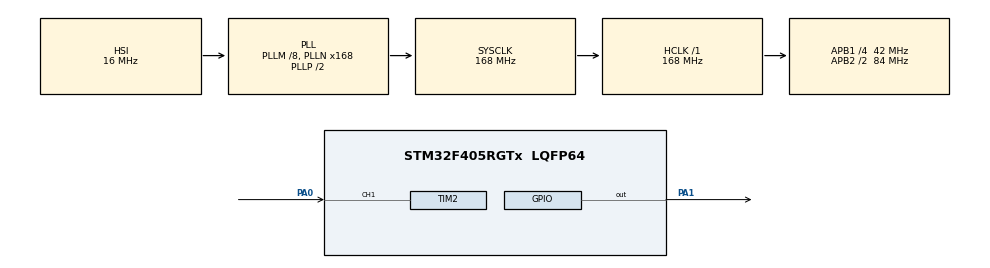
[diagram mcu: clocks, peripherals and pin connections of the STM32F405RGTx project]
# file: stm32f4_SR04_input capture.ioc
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Mcu.Family=STM32F4
Mcu.Name=STM32F405RGTx
Mcu.Package=LQFP64
NVIC.PriorityGroup=NVIC_PRIORITYGROUP_4
NVIC.TIM2_IRQn=true\:0\:0\:false\:false\:true\:true\:true\:true
PA0-WKUP.Signal=S_TIM2_CH1_ETR
PA1.GPIO_PuPd=GPIO_PULLUP
PA1.GPIO_Speed=GPIO_SPEED_FREQ_HIGH
PA1.Signal=GPIO_Output
PA13.Mode=Serial_Wire
PA13.Signal=SYS_JTMS-SWDIO
PA14.Mode=Serial_Wire
PA14.Signal=SYS_JTCK-SWCLK
PH0-OSC_IN.Mode=HSE-External-Oscillator
PH0-OSC_IN.Signal=RCC_OSC_IN
PH1-OSC_OUT.Mode=HSE-External-Oscillator
PH1-OSC_OUT.Signal=RCC_OSC_OUT
ProjectManager.HeapSize=0x200
ProjectManager.StackSize=0x400
ProjectManager.TargetToolchain=MDK-ARM V5.32
RCC.48MHZClocksFreq_Value=84000000
RCC.AHBFreq_Value=168000000
RCC.APB1CLKDivider=RCC_HCLK_DIV4
RCC.APB1Freq_Value=42000000
RCC.APB1TimFreq_Value=84000000
RCC.APB2CLKDivider=RCC_HCLK_DIV2
RCC.APB2Freq_Value=84000000
RCC.APB2TimFreq_Value=168000000
RCC.CortexFreq_Value=168000000
RCC.HCLKFreq_Value=168000000
RCC.HSE_VALUE=25000000
RCC.HSI_VALUE=16000000
RCC.LSE_VALUE=32768
RCC.PLLM=8
RCC.PLLN=168
RCC.SYSCLKFreq_VALUE=168000000
RCC.SYSCLKSource=RCC_SYSCLKSOURCE_PLLCLK
RCC.VCOOutputFreq_Value=336000000
SH.S_TIM2_CH1_ETR.0=TIM2_CH1,Input_Capture1_from_TI1
TIM2.Channel-Input_Capture1_from_TI1=TIM_CHANNEL_1
TIM2.Prescaler=167
VP_TIM2_VS_ClockSourceINT.Mode=Internal
board=custom

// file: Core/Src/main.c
/* USER CODE BEGIN Header */
/**
  ******************************************************************************
  * @file           : main.c
  * @brief          : Main program body
  ******************************************************************************
  * @attention
  *
  * Copyright (c) 2022 STMicroelectronics.
  * All rights reserved.
  *
  * This software is licensed under terms that can be found in the LICENSE file
  * in the root directory of this software component.
  * If no LICENSE file comes with this software, it is provided AS-IS.
	*
	******************************************************************************
	*说明
	******************************************************************************
	*使用了定时器2，设置为Internal Clock,输入捕获，预分频至主频-1
	*Trig引脚配置为推挽输出模式，上拉，设置在SR04.h文件
	*使用不同的定时器注意在SR04.h中修改
	*距离保存在浮点型distant中，可在Debug中查看
	******************************************************************************
	*/
/* USER CODE END Header */
#include "main.h"
#include "tim.h"
#include "gpio.h"

/* USER CODE BEGIN Includes */
#include "SR04.h"//超声波头文件
/* USER CODE END Includes */

void SystemClock_Config(void);

int main(void)
{

  /* MCU Configuration--------------------------------------------------------*/

  /* Reset of all peripherals, Initializes the Flash interface and the Systick. */
  HAL_Init();

  /* Configure the system clock */
  SystemClock_Config();

  /* Initialize all configured peripherals */
  MX_GPIO_Init();
  MX_TIM2_Init();

  /* Infinite loop */
  while (1)
  {

    /* USER CODE BEGIN 3 */
		SR04_GetData();
    HAL_Delay(1500);
  }
  /* USER CODE END 3 */
}

void SystemClock_Config(void)
{
  RCC_OscInitTypeDef RCC_OscInitStruct = {0};
  RCC_ClkInitTypeDef RCC_ClkInitStruct = {0};

  /** Configure the main internal regulator output voltage
  */
  __HAL_RCC_PWR_CLK_ENABLE();
  __HAL_PWR_VOLTAGESCALING_CONFIG(PWR_REGULATOR_VOLTAGE_SCALE1);

  /** Initializes the RCC Oscillators according to the specified parameters
  * in the RCC_OscInitTypeDef structure.
  */
  RCC_OscInitStruct.OscillatorType = RCC_OSCILLATORTYPE_HSI;
  RCC_OscInitStruct.HSIState = RCC_HSI_ON;
  RCC_OscInitStruct.HSICalibrationValue = RCC_HSICALIBRATION_DEFAULT;
  RCC_OscInitStruct.PLL.PLLState = RCC_PLL_ON;
  RCC_OscInitStruct.PLL.PLLSource = RCC_PLLSOURCE_HSI;
  RCC_OscInitStruct.PLL.PLLM = 8;
  RCC_OscInitStruct.PLL.PLLN = 168;
  RCC_OscInitStruct.PLL.PLLP = RCC_PLLP_DIV2;
  RCC_OscInitStruct.PLL.PLLQ = 4;
  if (HAL_RCC_OscConfig(&RCC_OscInitStruct) != HAL_OK)
  {
    Error_Handler();
  }

  /** Initializes the CPU, AHB and APB buses clocks
  */
  RCC_ClkInitStruct.ClockType = RCC_CLOCKTYPE_HCLK|RCC_CLOCKTYPE_SYSCLK
                              |RCC_CLOCKTYPE_PCLK1|RCC_CLOCKTYPE_PCLK2;
  RCC_ClkInitStruct.SYSCLKSource = RCC_SYSCLKSOURCE_PLLCLK;
  RCC_ClkInitStruct.AHBCLKDivider = RCC_SYSCLK_DIV1;
  RCC_ClkInitStruct.APB1CLKDivider = RCC_HCLK_DIV4;
  RCC_ClkInitStruct.APB2CLKDivider = RCC_HCLK_DIV2;

  if (HAL_RCC_ClockConfig(&RCC_ClkInitStruct, FLASH_LATENCY_5) != HAL_OK)
  {
    Error_Handler();
  }
}

void Error_Handler(void)
{
  __disable_irq();
  while (1)
  {
  }
}
